# MCU_I3C0_VBP2APB_WRAP_CORE_VBP_MIPI_I3C_MST register map
Vendor: Texas Instruments
Peripheral module from a debugger description file (folder J721S2).
Registers are 32-bit, read-write, reset 0x0 unless marked. A register's access mark holds for its fields unless they carry their own. Offsets are as the file gives them; lines under a group give offsets from that group; [hi:lo] are bit positions; {n}, {i} and the like mark numbered series; 'fields as' and 'values as' point back to an identical list; <NAME> marks a mode.

## MCU_I3C0_VBP2APB_WRAP_CORE_VBP_MIPI_I3C_MST (part 1 of 2)
0x00 VBP2APB_WRAP__CORE_VBP__MIPI_I3C_MST_REGS_DEV_ID ro reset 0x5034 — ID Register for Cadence I3C Master IP - Read Only register that provides identification information for the controller.
  [15:0] DEV_ID — Device ID: Unique IP identifier within Cadence IP portfolio [reset = 0x5034].
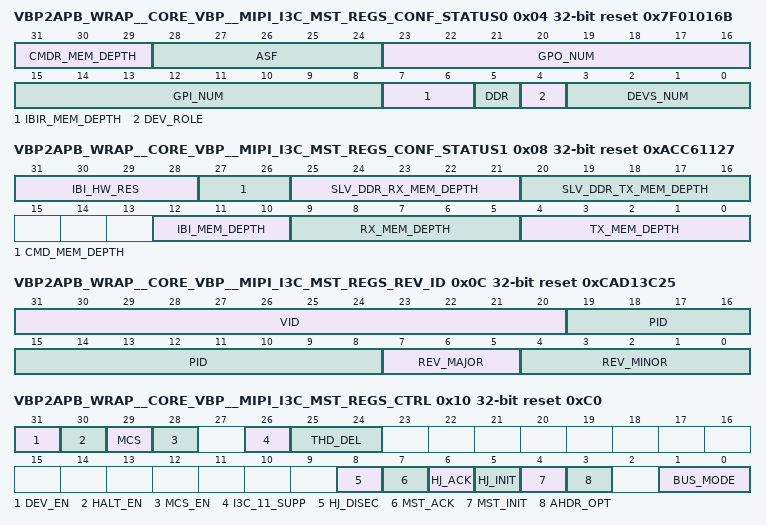
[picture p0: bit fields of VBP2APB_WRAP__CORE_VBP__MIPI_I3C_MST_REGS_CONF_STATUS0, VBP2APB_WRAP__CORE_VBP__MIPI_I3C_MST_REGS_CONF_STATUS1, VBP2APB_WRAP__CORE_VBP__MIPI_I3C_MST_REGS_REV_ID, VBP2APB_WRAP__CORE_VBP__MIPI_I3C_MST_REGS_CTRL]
0x04 VBP2APB_WRAP__CORE_VBP__MIPI_I3C_MST_REGS_CONF_STATUS0 ro reset 0x7F01016B — The read-only Configuration Status Register 0 indicates the hardware configuration options chosen for implementation of I3C-Master.
  [31:29] CMDR_MEM_DEPTH — Indicates depth of Command Response Queue: 000 - Memory has depth of 4 001 - Memory has depth of 8 010 - Memory has depth of 16 011 - Memory has depth of 32 100 - Memory has depth of 64 101 - 111 - N/A Note: 2^[2 + cmdr_mem_depth] = actual depth of CMD Response memory.
  [28:24] ASF — Indicates supported ASF checks: asf[4] - ECC Check enabled asf[3] - Integrity Check enabled asf[2] - CSR/DAP Check enabled asf[1] - Trans. Timeout Check enabled asf[0] - Protocol Faults Check enabled
  [23:16] GPO_NUM — Returns the value of User GPO [1-126].
  [15:8] GPI_NUM — Returns the value of User GPI [1-126].
  [7:6] IBIR_MEM_DEPTH — Indicates depth of IBI Response Queue: 00 - Memory has depth of 4 01 - Memory has depth of 8 10 - Memory has depth of 16 11 - Memory has depth of 32 Note: 2^[2 + ibir_mem_depth] = actual depth of IBI Response memory.
  [5] DDR — Indicates if DDR is supported.
  [4] DEV_ROLE — Returns status of Device Role [MM/SM]: 0 - Main Master 1 - Secondary Master
  [3:0] DEVS_NUM — Returns the number of retaining registers for I3C Slave devices [Addresses and Characteristics], the max value is 11.
0x08 VBP2APB_WRAP__CORE_VBP__MIPI_I3C_MST_REGS_CONF_STATUS1 ro reset 0xACC61127 — The read-only Configuration Status Register 1 indicates the hardware configuration options chosen for implementation of I3C-Master.
  [31:28] IBI_HW_RES — Indicates HW resources for IBI capable devices: 0000 - SIR map for 1 Slave device 0001 - SIR map for 2 Slave devices ... 1010 - SIR map for 11 Slave devices 1101 - 1111 - N/A Note: ibi_rw_res + 1 = actual number of SIR map locations for IBI capable slave devices.
  [27:26] CMD_MEM_DEPTH — Indicates depth of Command Memories [0 and 1]: 00 - Memory has depth of 4 01 - Memory has depth of 8 10 - Memory has depth of 16 11 - Memory has depth of 32 Note: 2^[2 + cmd_mem_depth] = actual depth of CMD0 and CMD1 memories.
  [25:21] SLV_DDR_RX_MEM_DEPTH — Indicates depth of Slave DDR Rx Memory: 00000 - Memory has depth of 8 00001 - Memory has depth of 16 ... 01101 - Memory has depth of 65536 01110 - 11111 - N/A Note: 2^[3 + slv_ddr_rx_mem_depth] = actual depth of Slave DDR Rx Data memory. When DDR is not supported field returns 5'b00000.
  [20:16] SLV_DDR_TX_MEM_DEPTH — Indicates depth of Slave DDR Tx Memory: 00000 - Memory has depth of 8 00001 - Memory has depth of 16 ... 01101 - Memory has depth of 65536 01110 - 11111 - N/A Note: 2^[3 + slv_ddr_tx_mem_depth] = actual depth of Slave DDR Tx Data memory. When DDR is not supported field returns 5'b00000.
  [12:10] IBI_MEM_DEPTH — Indicates depth of In-Band Interrupt Memory: 000 - Memory has depth of 2 001 - Memory has depth of 4 ... 101 - Memory has depth of 64 110 - 111 - N/A Note: 2^[1 + ibi_mem_depth] = actual depth of IBI Data memory.
  [9:5] RX_MEM_DEPTH — Indicates depth of Rx Data Memory: 00000 - Memory has depth of 8 00001 - Memory has depth of 16 ... 01101 - Memory has depth of 65536 01110 - 11111 - N/A Note: 2^[3 + rx_mem_depth] = actual depth of Rx Data memory.
  [4:0] TX_MEM_DEPTH — Indicates depth of Tx Data Memory: 00000 - Memory has depth of 8 00001 - Memory has depth of 16 ... 01101 - Memory has depth of 65536 01110 - 11111 - N/A Note: 2^[3 + tx_mem_depth] = actual depth of Tx Data memory.
0x0C VBP2APB_WRAP__CORE_VBP__MIPI_I3C_MST_REGS_REV_ID ro reset 0xCAD13C25 — This register gives an information about particular version of the IP.
  [31:20] VID — VENDOR_ID: IP vendor ID affected to Cadence I3C Master controller [reset = 0xCAD].
  [19:8] PID — PRODUCT_ID: unique IP identifier within CDNS IP portfolio [reset = 0x13C].
  [7:5] REV_MAJOR — X: Major revision value [1]. rXYYv1p0 - current version r105v1p0
  [4:0] REV_MINOR — Y: Minor revision value [05]. rXYYv1p0 - current version r105v1p0
0x10 VBP2APB_WRAP__CORE_VBP__MIPI_I3C_MST_REGS_CTRL access per field reset 0xC0 — Control Register for Cadence I3C Master IP - register that provides main control and configuration options for the controller.
  [31] DEV_EN rw — When set HIGH the I3C-Master is enabled and it can initiates the I3C/I2C transactions. Also write access to the following fields of various registers is forbidden : CTRL.bus_mode CTRL.ahdr_opt CTRL.halt_en PRESCL_CTRL0.i3c PRESCL_CTRL0.i2c PRESCL_CTRL1.od_low PRESCL_CTRL1.pp_low When set LOW the I3C-Master is disabled and access to the key control fields that listed above is available. If this bit is being set to 0 during ongoing transfer then it will wait until the transfer completion and then the controller will be disabled. The actual status of the Cadence I3C Master IP is returned by MST_STATUS0.idle bit of Status Register and this field should be checked before accessing key control fields.
  [30] HALT_EN rw — Enable[1]/Disable[0] Halt on Abort function.
  [29] MCS wo — Manual Command Start writing 1 starts execution of the commands currently in CMD Memories. Self-cleared bit. Relevant only if MCS_EN bit [CTRL.mcs_en] set to 1, disregarded otherwise.
  [28] MCS_EN rw — Manual Command Start Enable if set 1 the IP will wait with starting of command execution until MCS but [CTRL.mcs] would be set 1. If set to 0, the IP will start execute commands automatically as soon as at lease one is present in the CMD MEM and the MCS [CTRL.mcs] bit is disregarded.
  [26] I3C_11_SUPP rw — Enables support for timing parameter that has been changed in v1.1, i.e. tCASr_min. If: - 1'b0 - then tCASr_min = tCAS_min [as per MIPI spec v1.0] - 1'b1 - then tCASr_min = tCAS_min/2 [as per draft version of MIPI spec v1.1]
  [25:24] THD_DEL rw — Data Hold Time Delay, field that provides option to add data hold delay with respect to the SCL clock on which data on SDA is launched [applied only during actual Data transfer]: 00 - adds delay of 3x sys_clk clock cycles 01 - adds delay of 2x sys_clk clock cycles 10 - adds delay of 1x sys_clk clock cycles 11 - no delay [data is launched simultaneously with SCL clock edge]
  [8] HJ_DISEC rw — This bit controls the HW response for ACK'ed HJ request. When set HIGH, then the DISEC CCC is used. Otherwise, if set LOW the ENTDAA CCC is used. This control bit is meaningful if hj_ack=1 and controller operates in Main Master configuration.
  [7] MST_ACK rw — Specifies ACK response type for GETACCMST CCC, it can be either ACK response type [mst_ack = 1] or NACK response type [mst_ack = 0]. This control bit is meaningful in Slave Mode only.
  [6] HJ_ACK rw — Specifies ACK response type for HJ request, it can be either ACK response type [hj_ack = 1] or NACK response type [hj_ack = 0]. For Secondary Master configuration, this bit tied off to 0.
  [5] HJ_INIT wo — Initiate HJ request - applicable only for Secondary master in slave mode. Self-cleared bit.
  [4] MST_INIT wo — Initiate Mastership request - applicable only in slave mode. When set in master mode this bit has no effect. Self-cleared bit.
  [3] AHDR_OPT rw — Enable[1]/Disable[0] the Address Header optimization. If enabled, FW needs to restrict DAs to 0x03 - 0x3F range.
  [1:0] BUS_MODE rw — Bus Mode 00 : Pure Bus Mode 01 : Invalid Config 10 : Mixed Fast Bus Mode 11 : Mixed Slow/Limited Bus Mode
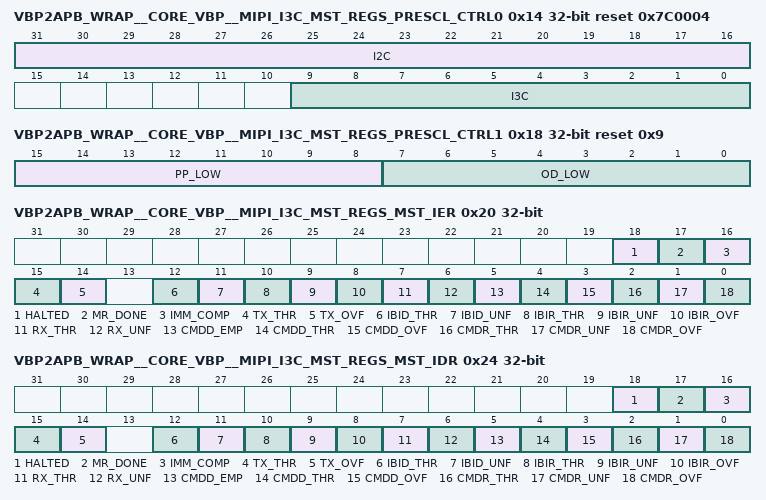
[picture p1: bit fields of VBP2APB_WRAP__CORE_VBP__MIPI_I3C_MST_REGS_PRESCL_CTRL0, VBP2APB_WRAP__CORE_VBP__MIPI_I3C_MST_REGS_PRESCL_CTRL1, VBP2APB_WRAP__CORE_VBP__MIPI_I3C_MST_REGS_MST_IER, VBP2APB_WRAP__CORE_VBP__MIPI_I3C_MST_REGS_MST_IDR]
0x14 VBP2APB_WRAP__CORE_VBP__MIPI_I3C_MST_REGS_PRESCL_CTRL0 reset 0x7C0004 — Prescale settings for SDR/I2C modes
  [31:16] I2C — Prescaler value for I2C SCL clock generation. It should be generated based on sys clock freq and should be 5x w.r.t. to the slowest I2C device's SCL speed: presc_ctl_i2c[15:0] = sys_clk_freq / [i2c_freq * 5] - 1'b1 if presc_ctl_i2c[15:0]==0 - no sys_clk division
  [9:0] I3C — Prescaler value for I3C Push-Pull SDR Mode SCL clock generation. When the bus is configured in mixed fast mode, the resulting SCL frequency must be faster than 11MHz. It should be generated based on sys clock freq and should be 4x w.r.t. to the SDR SCL speed: presc_ctl_i3c[9:0] = [sys_clk_freq / sdr_freq * 4] - 1'b1 If sys_clk == 4*sdr_freq, presc_ctl_i3c[9:0] should be 0
0x18 VBP2APB_WRAP__CORE_VBP__MIPI_I3C_MST_REGS_PRESCL_CTRL1 reset 0x9 — Prescale settings related to Open Drain / Push Pull I3C timings
  [15:8] PP_LOW — Counter for low period of SCL clock for Push Pull in I3C. When particular I3C device does not support Max SCL speed, low period stretching is required for PP as well. Controller will determine that by inspecting BCR[0] bit. When BCR[0] is 0, SCL waveform will have constant asymmetric ratio in Push-Pull mode as it will be calculated by 1/4 SCL * [pp_low + 2]. The resolution used is 1/4 SDR SCL clock. FW need to ensure 1/4 SCL * [pp_low + 2] >= minimum low period duration for the particular device. When BCR[0] is 1, PP timings will have 50/50 DC.
  [7:0] OD_LOW — Counter for low period of SCL clock for Open Drain in I3C. SCL waveform will have constant asymmetric ratio in OD as it will be calculated by 1/4 SCL * [od_low + 2]. The resolution used is 1/4 SDR SCL clock. FW need to ensure 1/4 SCL * [od_low + 2] >= 160ns.
0x20 VBP2APB_WRAP__CORE_VBP__MIPI_I3C_MST_REGS_MST_IER access per field — The write only Interrupt Enable Register is used to enable interrupts by setting bits in the read only Interrupt Mask Register - Master Mode (MST_IMR). See Interrupt Status Register - Master Mode (MST_ISR) description for details on specific interrupt conditions. When any bit is written high, the corresponding interrupt is enabled. Writing a low to any bit has no effect.
  [18] HALTED wo — Controller in halted state.
  [17] MR_DONE wo — Mastership handoff done Enable.
  [16] IMM_COMP wo — Immediate Commmand Completed Enable
  [15] TX_THR wo — Tx Data Threshold Enable.
  [14] TX_OVF wo — Tx Data MEM Underflow Enable
  [12] IBID_THR wo — IBI Data MEM threshold Enable.
  [11] IBID_UNF wo — IBI Data MEM underflow Enable.
  [10] IBIR_THR wo — IBI Response Queue threshold Enable
  [9] IBIR_UNF wo — IBI Response Queue underflow Enable
  [8] IBIR_OVF wo — IBI Response Queue onverflow Enable.
  [7] RX_THR wo — Rx Data MEM threshold Enable.
  [6] RX_UNF wo — Rx Data MEM underflow Enable.
  [5] CMDD_EMP wo — Command Request Queue Empty Enable.
  [4] CMDD_THR wo — Command Request Queue Threshold Enable.
  [3] CMDD_OVF wo — Command Request Queue Overflow Enable.
  [2] CMDR_THR wo — Command Response Queue Threshold Enable.
  [1] CMDR_UNF wo — Command Response Queue Underflow Enable.
  [0] CMDR_OVF wo — Command Response Queue Overflow Enable.
0x24 VBP2APB_WRAP__CORE_VBP__MIPI_I3C_MST_REGS_MST_IDR access per field — The write only Interrupt Disable Register is used to disable interrupts by clearing the bits in the read only Interrupt Mask Register - Master Mode (MST_IMR). See Interrupt Status Register - Master Mode (MST_ISR) description for details on specific interrupt conditions. When any bit is written high, the corresponding interrupt is disabled. Writing a low to any bit has no effect.
  [18] HALTED wo — Controller in halted state.
  [17] MR_DONE wo — Mastership handoff done Disable.
  [16] IMM_COMP wo — Immediate Commmand Completed Disable
  [15] TX_THR wo — Tx Data Threshold Disable.
  [14] TX_OVF wo — Tx Data MEM Underflow Disable
  [12] IBID_THR wo — IBI Data MEM threshold Disable.
  [11] IBID_UNF wo — IBI Data MEM underflow Disable.
  [10] IBIR_THR wo — IBI Response Queue threshold Disable
  [9] IBIR_UNF wo — IBI Response Queue underflow Disable
  [8] IBIR_OVF wo — IBI Response Queue onverflow Disable.
  [7] RX_THR wo — Rx Data MEM threshold Disable.
  [6] RX_UNF wo — Rx Data MEM underflow Disable.
  [5] CMDD_EMP wo — Command Request Queue Empty Disable.
  [4] CMDD_THR wo — Command Request Queue Threshold Disable.
  [3] CMDD_OVF wo — Command Request Queue Overflow Disable.
  [2] CMDR_THR wo — Command Response Queue Threshold Disable.
  [1] CMDR_UNF wo — Command Response Queue Underflow Disable.
  [0] CMDR_OVF wo — Command Response Queue Overflow Disable.
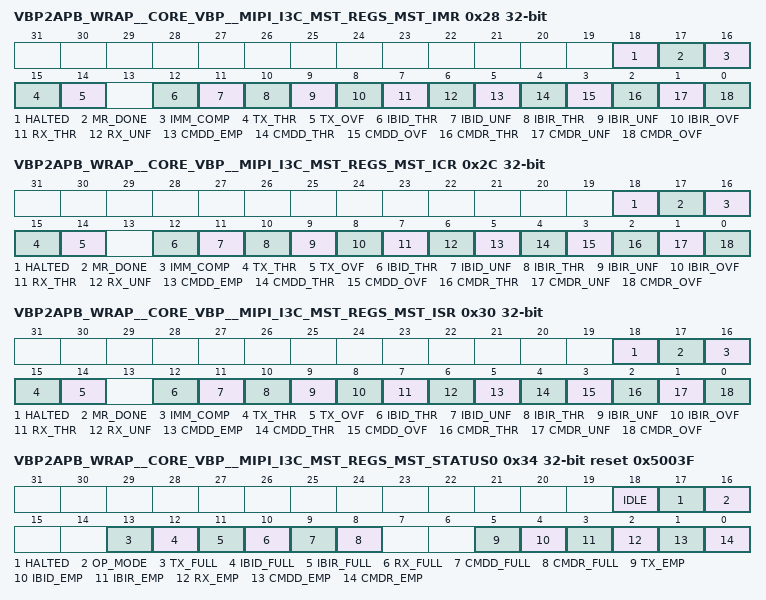
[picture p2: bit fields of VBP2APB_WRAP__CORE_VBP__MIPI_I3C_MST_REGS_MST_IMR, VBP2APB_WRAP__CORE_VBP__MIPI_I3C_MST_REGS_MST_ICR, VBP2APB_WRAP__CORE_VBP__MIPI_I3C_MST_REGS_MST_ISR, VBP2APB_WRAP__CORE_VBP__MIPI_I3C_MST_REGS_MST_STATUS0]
0x28 VBP2APB_WRAP__CORE_VBP__MIPI_I3C_MST_REGS_MST_IMR ro — This read only register, indicates the current state of the interrupts mask. See Interrupt Status Register - Master Mode (MST_ISR) description for details on specific interrupt conditions. A high value indicates the interrupt is enabled to generate an interrupt. A low value indicates the interrupt is disabled from generating an interrupt (masked).
  [18] HALTED — Controller in halted state.
  [17] MR_DONE — Mastership handoff done Mask.
  [16] IMM_COMP — Immediate Commmand Completed Mask
  [15] TX_THR — Tx Data Threshold Mask.
  [14] TX_OVF — Tx Data MEM Underflow Mask
  [12] IBID_THR — IBI Data MEM threshold Mask.
  [11] IBID_UNF — IBI Data MEM underflow Mask.
  [10] IBIR_THR — IBI Response Queue threshold Mask
  [9] IBIR_UNF — IBI Response Queue underflow Mask
  [8] IBIR_OVF — IBI Response Queue onverflow Mask.
  [7] RX_THR — Rx Data MEM threshold Mask.
  [6] RX_UNF — Rx Data MEM underflow Mask.
  [5] CMDD_EMP — Command Request Queue Empty Mask.
  [4] CMDD_THR — Command Request Queue Threshold Mask.
  [3] CMDD_OVF — Command Request Queue Overflow Mask.
  [2] CMDR_THR — Command Response Queue Threshold Mask.
  [1] CMDR_UNF — Command Response Queue Underflow Mask.
  [0] CMDR_OVF — Command Response Queue Overflow Mask.
0x2C VBP2APB_WRAP__CORE_VBP__MIPI_I3C_MST_REGS_MST_ICR access per field — Interrupt Clear Register for Master Mode of the cdnsi3c_master controller. Write 1 to clear (change from 1 to 0) corresponding bit in MST_ISR. Writing 0 has no effect
  [18] HALTED wo — Controller is in halted state.
  [17] MR_DONE wo — Mastership handoff done Mask.
  [16] IMM_COMP wo — Immediate Commmand Completed Mask
  [15] TX_THR wo — Tx Data Threshold Mask.
  [14] TX_OVF wo — Tx Data MEM Underflow Mask
  [12] IBID_THR wo — IBI Data MEM threshold Mask.
  [11] IBID_UNF wo — IBI Data MEM underflow Mask.
  [10] IBIR_THR wo — IBI Response Queue threshold Mask
  [9] IBIR_UNF wo — IBI Response Queue underflow Mask
  [8] IBIR_OVF wo — IBI Response Queue onverflow Mask.
  [7] RX_THR wo — Rx Data MEM threshold Mask.
  [6] RX_UNF wo — Rx Data MEM underflow Mask.
  [5] CMDD_EMP wo — Command Request Queue Empty Mask.
  [4] CMDD_THR wo — Command Request Queue Threshold Mask.
  [3] CMDD_OVF wo — Command Request Queue Overflow Mask.
  [2] CMDR_THR wo — Command Response Queue Threshold Mask.
  [1] CMDR_UNF wo — Command Response Queue Underflow Mask.
  [0] CMDR_OVF wo — Command Response Queue Overflow Mask.
0x30 VBP2APB_WRAP__CORE_VBP__MIPI_I3C_MST_REGS_MST_ISR ro — Interrupt Status Register for Master Mode of the cdnsi3c_master controller
  [18] HALTED — Controller in Halted state. This event is asserted on the second abort has occured during Read operation [if CTRL.halt_en=1] or in case of Rx DATA Buffer is full [regardless of CTRL.halt_en state].
  [17] MR_DONE — Mastership handoff Done. This event is triggered whenever Mastership Request procedure is completed.
  [16] IMM_COMP — Immediate Commmand Completed. Is asserted when immediate command is completed.
  [15] TX_THR — Tx DATA Buffer Threshold. It is set when number of bytes in the Tx DATA Buffer reaches value programmed in the TX_RX_THR_CTRL.tx_thr field.
  [14] TX_OVF — Tx DATA Buffer Overflow. Set if host attempts to write to Tx DATA Buffer which is already full
  [12] IBID_THR — IBI DATA Buffer Threshold. It is set when number of butes in the IBI DATA Buffer reaches value programmed in the CMD_IBI_THR_CTRL.ibid_thr field.
  [11] IBID_UNF — IBI DATA Buffer Underflow. It is set when FW attempts to read from empty IBI DATA Buffer.
  [10] IBIR_THR — IBI Response Buffer Threshold. It is set when number of butes in the IBI Response Buffer reaches value programmed in the CMD_IBI_THR_CTRL.ibir_thr field.
  [9] IBIR_UNF — IBI Response Buffer Underflow. It is set when FW attempts to read from empty IBI Response Buffer.
  [8] IBIR_OVF — IBI Response Buffer Overflow. Set if the new slave-initiated request is received while IBI Response Buffer is already full.
  [7] RX_THR — Rx Data Buffer Threshold. It is set when number of bytes in the Rx DATA Buffer reaches value programmed in the TX_RX_THR_CTRL.rx_thr field.
  [6] RX_UNF — Rx Data Buffer Underflow. Set if the host attempts to read from the empty Rx DATA Buffer.
  [5] CMDD_EMP — Command Request Queue Empty. It is set as soon as the last command in the Command Queue is completed [simultaneously with comp flag].
  [4] CMDD_THR — Command Request Queue Threshold. It is set when number of bytes in the Command Buffer reaches value programmed in the CMD_IBI_THR_CTRL.cmdd_thr field.
  [3] CMDD_OVF — Command Request Queue Overflow. It is set whenever Command Buffer is full and a new command is received from the host. In this case contents of the Command Buffer remains unchanged.
  [2] CMDR_THR — Command Response Queue Threshold. It is set when number of bytes in the Command Response Buffer reaches value programmed in the CMD_IBI_THR_CTRL.cmdr_thr field.
  [1] CMDR_UNF — Command Response Queue Underflow. It is set when FW attempts to read from empty Command Response Buffer.
  [0] CMDR_OVF — Command Response Queue Overflow. It is set whenever Command Response Buffer is full and a new response is received. In this case contents of the Command Response Buffer remains unchanged.
0x34 VBP2APB_WRAP__CORE_VBP__MIPI_I3C_MST_REGS_MST_STATUS0 access not given reset 0x5003F — Status Register for Cadence I3C Master IP, meaningful only when controller operates in Master mode.
  [18] IDLE ro — Indicates when the core is IDLE and ready to accept new commands. When CTRL.dev_en is deasserted, FW should poll this reg in order to ensure that core completed its last command. It is advisable to use this bit in order to ensure that currently the core is IDLE and CTRL register can be changed.
  [17] HALTED — Core Halted. This status bit will be asserted on the second abort has occurred during Read operation [if CTRL.halt_en=1] or in case of Rx DATA FIFO is full [regardless of CTRL.halt_en state]. Writing 1 will unhalt the controllers operation. (access R/W1TC)
  [16] OP_MODE ro — Indicates current mode of the controller: 0 - Slave mode; 1 - Master mode. For Main Master configuration the reset value is 1 For Secondary Master configuration the reset value is 0 Set by HW.
  [13] TX_FULL ro — Tx DATA Memory is Full.
  [12] IBID_FULL ro — IBI DATA Memory is Full.
  [11] IBIR_FULL ro — IBI Response Queue is Full.
  [10] RX_FULL ro — Rx DATA Memory is Full.
  [9] CMDD_FULL ro — CMD DATA Queue is Full.
  [8] CMDR_FULL ro — CMD Response Queue is Full.
  [5] TX_EMP ro — TX DATA Memory is Empty.
  [4] IBID_EMP ro — IBI DATA Memory is Empty.
  [3] IBIR_EMP ro — IBI Response Queue is Empty.
  [2] RX_EMP ro — RX DATA Memory is Empty.
  [1] CMDD_EMP ro — CMD Descriptor Queue is Empty.
  [0] CMDR_EMP ro — CMD Response Queue is Empty.
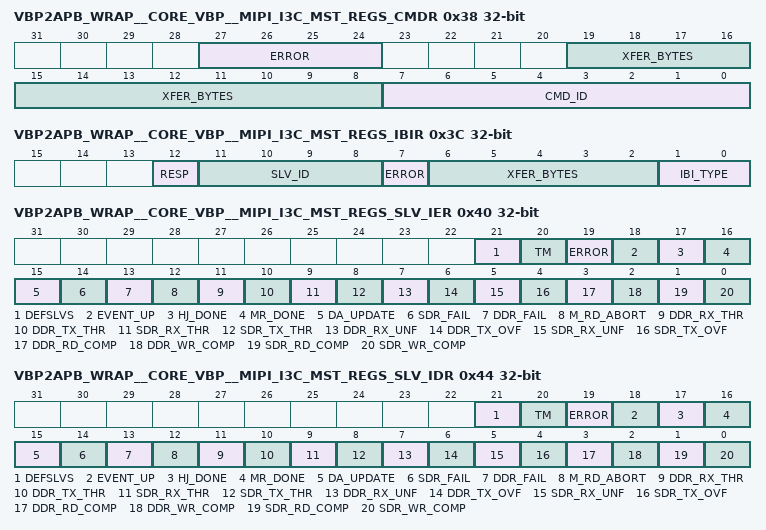
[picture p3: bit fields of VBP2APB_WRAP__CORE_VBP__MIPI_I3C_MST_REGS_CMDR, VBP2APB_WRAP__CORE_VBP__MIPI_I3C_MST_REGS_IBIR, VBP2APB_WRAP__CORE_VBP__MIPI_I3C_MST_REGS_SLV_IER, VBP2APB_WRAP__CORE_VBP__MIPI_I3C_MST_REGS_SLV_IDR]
0x38 VBP2APB_WRAP__CORE_VBP__MIPI_I3C_MST_REGS_CMDR ro — Command Response Queue - stores status on completion of each command, works on FIFO-basis.
  [27:24] ERROR — Error Code - contains the code of an error that has occured during command execution: - 4'h0: No Error, - 4'h1: DDR Preamble Error, - 4'h2: DDR Parity Error, - 4'h3: DDR Rx FIFO Overflow, - 4'h4: DDR Tx FIFO Underflow, - 4'h5: M0 Error, - 4'h6: M1 Error, - 4'h7: M2 Error, - 4'h8: MST Abort, - 4'h9: NACK Response, - 4'hA: Invalid DA, - 4'hB: DDR Dropped.
  [19:8] XFER_BYTES — The number of transferred bytes [SDR] or transferred words [DDR] during command execution. Will be set correctly for CCC commands as well even for those without payload [to zero value].
  [7:0] CMD_ID — Command Identifier - equals to the value of CMD_ID field of Command Descriptor for given command. There are following exceptions in a form of HW-initiated commands: - DAA after HJ-ACK response - ID field is returned as 8'hFF - DISEC after HJ-ACK response - ID field is returned as 8'hFE - Auto-Repeated Command after M0 Error - ID field equals to the CMD_ID of command that has been repeated
0x3C VBP2APB_WRAP__CORE_VBP__MIPI_I3C_MST_REGS_IBIR ro — Stores status of SIR on its completion, works on FIFO-basis.
  [12] RESP — Master response. If set HIGH then IBI has been ACKed, NACK response otherwise.
  [11:8] SLV_ID — ID of slave that issued the request, as stored in retaining registers.
  [7] ERROR — Error. Set HIGH if IBI DATA Buffer overflow has occured during the transaction.
  [6:2] XFER_BYTES — Number of received DATA bytes.
  [1:0] IBI_TYPE — Type of IBI Request. This field contains the type of serviced IBI message. Type codes: - 2'h0: In-Band Interrupt, - 2'h1: Hot-Join Request, - 2'h2: Masterhip Takeover Request.
0x40 VBP2APB_WRAP__CORE_VBP__MIPI_I3C_MST_REGS_SLV_IER wo — The write only Interrupt Enable Register is used to enable interrupts by setting bits in the read only Interrupt Mask Register - Slave Mode (SLV_IMR). See Interrupt Status Register - Slave Mode (SLV_ISR) description for details on specific interrupt conditions. When any bit is written high, the corresponding interrupt is enabled. Writing a low to any bit has no effect.
  [21] DEFSLVS — DEFSLVS interrupt Enable.
  [20] TM — TM interrupt Enable.
  [19] ERROR — ERROR interrupt Enable.
  [18] EVENT_UP — EVENT_UP interrupt Enable.
  [17] HJ_DONE — HJ_DONE interrupt Enable.
  [16] MR_DONE — MR_DONE interrupt Enable.
  [15] DA_UPDATE — DA_UPDATE interrupt Enable
  [14] SDR_FAIL — SDR_FAIL interrupt Enable
  [13] DDR_FAIL — DDR_FAIL interrupt Enable
  [12] M_RD_ABORT — M_RD_ABORT interrupt Enable.
  [11] DDR_RX_THR — DDR_RX_THR interrupt Enable.
  [10] DDR_TX_THR — DDR_TX_THR interrupt Enable.
  [9] SDR_RX_THR — SDR_RX_THR interrupt Enable.
  [8] SDR_TX_THR — SLV_SDR_TX_THR interrupt Enable.
  [7] DDR_RX_UNF — DDR_RX_UNF interrupt Enable.
  [6] DDR_TX_OVF — DDR_TX_OVF interrupt Enable.
  [5] SDR_RX_UNF — SDR_RX_UNF interrupt Enable.
  [4] SDR_TX_OVF — SDR_TX_OVF interrupt Enable.
  [3] DDR_RD_COMP — DDR_RD_COMP interrupt Enable.
  [2] DDR_WR_COMP — DDR_WR_COMP interrupt Enable.
  [1] SDR_RD_COMP — SDR_RD_COMP interrupt Enable.
  [0] SDR_WR_COMP — SDR_WR_COMP interrupt Enable.
0x44 VBP2APB_WRAP__CORE_VBP__MIPI_I3C_MST_REGS_SLV_IDR wo — The write only Interrupt Disable Register is used to disable interrupts by clearing the bits in the read only Interrupt Mask Register - Slave Mode (SLV_IMR). See Interrupt Status Register - Slave Mode (SLV_ISR) description for details on specific interrupt conditions. When any bit is written high, the corresponding interrupt is disabled. Writing a low to any bit has no effect.
  [21] DEFSLVS — DEFSLVS interrupt Disable.
  [20] TM — TM interrupt Disable.
  [19] ERROR — ERROR interrupt Disable.
  [18] EVENT_UP — EVENT_UP interrupt Disable.
  [17] HJ_DONE — HJ_DONE interrupt Disable.
  [16] MR_DONE — MR_DONE interrupt Disable.
  [15] DA_UPDATE — DA_UPDATE interrupt Disable.
  [14] SDR_FAIL — SDR_FAIL interrupt Disable
  [13] DDR_FAIL — DDR_FAIL interrupt Disable
  [12] M_RD_ABORT — M_RD_ABORT interrupt Disable.
  [11] DDR_RX_THR — DDR_RX_THR interrupt Disable.
  [10] DDR_TX_THR — DDR_TX_THR interrupt Disable.
  [9] SDR_RX_THR — SDR_RX_THR interrupt Disable.
  [8] SDR_TX_THR — SDR_TX_THR interrupt Disable.
  [7] DDR_RX_UNF — DDR_RX_UNF interrupt Disable.
  [6] DDR_TX_OVF — DDR_TX_OVF interrupt Disable.
  [5] SDR_RX_UNF — SDR_RX_UNF interrupt Disable.
  [4] SDR_TX_OVF — SDR_TX_OVF interrupt Disable.
  [3] DDR_RD_COMP — DDR_RD_COMP interrupt Disable.
  [2] DDR_WR_COMP — DDR_WR_COMP interrupt Disable.
  [1] SDR_RD_COMP — SDR_RD_COMP interrupt Disable.
  [0] SDR_WR_COMP — SDR_WR_COMP interrupt Disable.
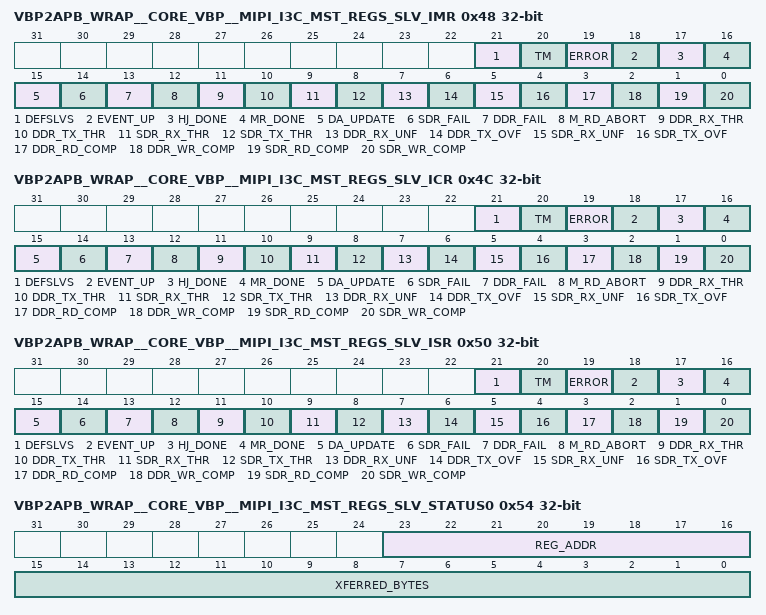
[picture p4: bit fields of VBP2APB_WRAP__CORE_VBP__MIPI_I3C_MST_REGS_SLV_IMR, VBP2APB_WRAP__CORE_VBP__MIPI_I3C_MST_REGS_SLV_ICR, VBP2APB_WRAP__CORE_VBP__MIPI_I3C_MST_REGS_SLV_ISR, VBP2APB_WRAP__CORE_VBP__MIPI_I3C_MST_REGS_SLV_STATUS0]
0x48 VBP2APB_WRAP__CORE_VBP__MIPI_I3C_MST_REGS_SLV_IMR ro — This read only register, indicates the current state of the interrupts mask. See Interrupt Status Register - Slave Mode (SLV_ISR) description for details on specific interrupt conditions. A high value indicates the interrupt is enabled to generate an interrupt. A low value indicates the interrupt is disabled from generating an interrupt (masked).
  [21] DEFSLVS — DEFSLVS interrupt Mask.
  [20] TM — TM interrupt Mask.
  [19] ERROR — ERROR interrupt Mask.
  [18] EVENT_UP — EVENT_UP interrupt Mask.
  [17] HJ_DONE — HJ_DONE interrupt Mask.
  [16] MR_DONE — MR_DONE interrupt Mask.
  [15] DA_UPDATE — DA_UPDATE interrupt Mask.
  [14] SDR_FAIL — SDR_FAIL interrupt Mask
  [13] DDR_FAIL — DDR_FAIL interrupt Mask
  [12] M_RD_ABORT — M_RD_ABORT interrupt Mask.
  [11] DDR_RX_THR — DDR_RX_THR interrupt Mask.
  [10] DDR_TX_THR — DDR_TX_THR interrupt Mask.
  [9] SDR_RX_THR — SDR_RX_THR interrupt Mask.
  [8] SDR_TX_THR — SDR_TX_THR interrupt Mask.
  [7] DDR_RX_UNF — DDR_RX_UNF interrupt Mask.
  [6] DDR_TX_OVF — DDR_TX_OVF interrupt Mask.
  [5] SDR_RX_UNF — SDR_RX_UNF interrupt Mask.
  [4] SDR_TX_OVF — SDR_TX_OVF interrupt Mask.
  [3] DDR_RD_COMP — DDR_RD_COMP interrupt Mask.
  [2] DDR_WR_COMP — DDR_WR_COMP interrupt Mask.
  [1] SDR_RD_COMP — SDR_RD_COMP interrupt Mask.
  [0] SDR_WR_COMP — SDR_WR_COMP interrupt Mask.
0x4C VBP2APB_WRAP__CORE_VBP__MIPI_I3C_MST_REGS_SLV_ICR wo — Interrupt Clear Register for Slave Mode of the cdnsi3c_master controller. Write 1 to clear (change from 1 to 0) corresponding bit in SLV_ISR. Writing 0 has no effect
  [21] DEFSLVS — DEFSLVS interrupt Clear.
  [20] TM — TM interrupt Clear.
  [19] ERROR — ERROR interrupt Clear.
  [18] EVENT_UP — EVENT_UP interrupt Clear.
  [17] HJ_DONE — HJ_DONE interrupt Clear.
  [16] MR_DONE — MR_DONE interrupt Clear.
  [15] DA_UPDATE — DA_UPDATE interrupt Clear.
  [14] SDR_FAIL — SDR_FAIL interrupt Clear.
  [13] DDR_FAIL — DDR_FAIL interrupt Clear.
  [12] M_RD_ABORT — M_RD_ABORT interrupt Clear.
  [11] DDR_RX_THR — DDR_RX_THR interrupt Clear.
  [10] DDR_TX_THR — DDR_TX_THR interrupt Clear.
  [9] SDR_RX_THR — SDR_RX_THR interrupt Clear.
  [8] SDR_TX_THR — SDR_TX_THR interrupt Clear.
  [7] DDR_RX_UNF — DDR_RX_UNF interrupt Clear.
  [6] DDR_TX_OVF — DDR_TX_OVF interrupt Clear.
  [5] SDR_RX_UNF — SDR_RX_UNF interrupt Clear.
  [4] SDR_TX_OVF — SDR_TX_OVF interrupt Clear.
  [3] DDR_RD_COMP — DDR_RD_COMP interrupt Clear.
  [2] DDR_WR_COMP — DDR_WR_COMP interrupt Clear.
  [1] SDR_RD_COMP — SDR_RD_COMP interrupt Clear.
  [0] SDR_WR_COMP — SDR_WR_COMP interrupt Clear.
0x50 VBP2APB_WRAP__CORE_VBP__MIPI_I3C_MST_REGS_SLV_ISR ro — Interrupt Status Register for Slave Mode operation
  [21] DEFSLVS — This interrupt is triggered whenever I3C-Slave DEFSLVS CCC command is received.
  [20] TM — This interrupt is triggered whenever I3C-Slave is not in Test Mode and ENTTM CCC requests to enter general Test Mode.
  [19] ERROR — This event is triggered whenever SDR Error is detected - applicable for S0, S1, S2, S4 and S5 Errors from MIPI spec.
  [18] EVENT_UP — This event is triggered whenever DISEC CCC or ENEC CCC is received.
  [17] HJ_DONE — This event is triggered whenever Hot-Join request is completed.
  [16] MR_DONE — This event is triggered whenever Mastership Request is completed.
  [15] DA_UPDATE — This event is triggered whenever Dynamic Address of the device has been updated.
  [14] SDR_FAIL — This event is triggered whenever fail event during SDR transfer is detected [applicable for Private Write transfers only].
  [13] DDR_FAIL — This event is triggered whenever fail event during DDR transfer is detected.
  [12] M_RD_ABORT — Read Transfer Aborted by Master.
  [11] DDR_RX_THR — Slave DDR Rx DATA Buffer Threshold. It is set when the number of words in the Slave DDR Rx DATA Buffer reaches value programmed in SLV_DDR_TX_RX_THR_CTRL.slv_ddr_rx_thr field.
  [10] DDR_TX_THR — Slave DDR Tx DATA Buffer Threshold. It is set when the number of words in the Slave DDR Tx DATA Buffer reaches value programmed in SLV_DDR_TX_RX_THR_CTRL.slv_ddr_tx_thr field.
  [9] SDR_RX_THR — Rx DATA Buffer Threshold. It is set when the number of bytes in the Rx DATA Buffer reaches value programmed in TX_RX_THR_CTRL.rx_thr field.
  [8] SDR_TX_THR — Tx DATA Buffer Threshold. It is set when the number of bytes in the Tx DATA Buffer reaches value programmed in TX_RX_THR_CTRL.tx_thr field.
  [7] DDR_RX_UNF — Slave DDR Rx DATA Buffer Underflow. Set if host attempts to read from the empty Slave Rx DATA Buffer.
  [6] DDR_TX_OVF — Slave DDR Tx DATA Buffer Overflow. Set if host attepmts to write to Slvave DDR Tx DATA Buffer which is already full.
  [5] SDR_RX_UNF — Rx DATA Buffer Underflow. Set if host attempts to read from the empty Rx DATA Buffer.
  [4] SDR_TX_OVF — Tx DATA Buffer Overflow. Set if host attempts to write to Tx DATA Buffer which is already full.
  [3] DDR_RD_COMP — This bit is set whenever the Slave terminates the DDR Read transfer.
  [2] DDR_WR_COMP — This bit is set whenever the Master terminates the DDR Write transfer.
  [1] SDR_RD_COMP — This bit is set whenever the Slave terminates the SDR Private Read transfer.
  [0] SDR_WR_COMP — This bit is set whenever the Master terminates the SDR Private Write transfer.
0x54 VBP2APB_WRAP__CORE_VBP__MIPI_I3C_MST_REGS_SLV_STATUS0 ro — The read only Status 0 register (SLV_STATUS0) is provided to enable the continuous monitoring of the raw unmasked status information of the I3C-Master operating in Slave mode.
  [23:16] REG_ADDR — Private Read/Write Address.
  [15:0] XFERRED_BYTES — Number of transferred bytes in SDR transactions.
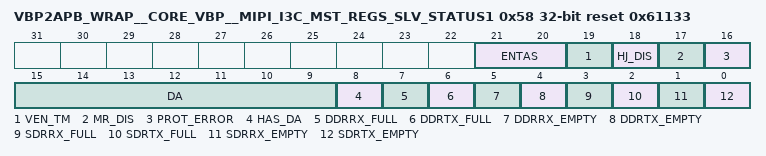
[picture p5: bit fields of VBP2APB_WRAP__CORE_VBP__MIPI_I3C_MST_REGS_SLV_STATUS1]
0x58 VBP2APB_WRAP__CORE_VBP__MIPI_I3C_MST_REGS_SLV_STATUS1 ro reset 0x61133 — The read only Status 1 register (SLV_STATUS1) is provided to enable the continuous monitoring of the raw unmasked status information of the I3C-Master operating in Slave mode.
  [21:20] ENTAS — Bits that indicate current Activity State. It is updated based on ENTASx CCC [broadcast or direct], by default is set to 2'b00.
  [19] VEN_TM — Vendor Test Mode. This bit is set whenever ENTTM CCC requests to enter general Test Mode. It remains HIGH until reception of another ENTTM CCC with different value.
  [18] HJ_DIS — Hot-Join Request is Disabled. This bit is set whenever HJ request is disabled by Current I3C-Master using DISEC CCC.
  [17] MR_DIS — Mastership Request is Disabled. This bit is set whenever MR request is disabled by Current I3C-Master using DISEC CCC.
  [16] PROT_ERROR — Protocol Error Condition Indicator. This bit is set whenever SDR error condition is detected by I3C-Master operating in Slave mode. It remains High until detection of recovery pattern.
  [15:9] DA — Current Slave Dynamic Address. Irrelevant if SLV_STATUS1.has_da bit is Low.
  [8] HAS_DA — This bit is set whenever Slave has Dynamic Address assigned. Tied HIGH when controller operates as Main Master device class.
  [7] DDRRX_FULL — This bit is set whenever Slave DDR Rx DATA Buffer is full.
  [6] DDRTX_FULL — This bit is set whenever Slave DDR Tx DATA Buffer is full.
  [5] DDRRX_EMPTY — This bit is set whenever Slave DDR Rx DATA Buffer is empty.
  [4] DDRTX_EMPTY — This bit is set whenever Slave DDR Tx DATA Buffer is empty.
  [3] SDRRX_FULL — This bit is set whenever Rx DATA Buffer is full.
  [2] SDRTX_FULL — This bit is set whenever Tx DATA Buffer is full.
  [1] SDRRX_EMPTY — This bit is set whenever Rx DATA Buffer is empty.
  [0] SDRTX_EMPTY — This bit is set whenever Tx DATA Buffer is empty.
